# D1H register map
Vendor: Allwinner; File version: 1.0
Registers are 32-bit, read-write, reset 0x0 unless marked. A register's access mark holds for its fields unless they carry their own. Offsets are from the block's base; [hi:lo] are bit positions; {n}, {i} and the like mark numbered series; 'fields as' and 'values as' point back to an identical list.

## GPIO — Gerneral Purpose Input/Output
Base 0x02000000
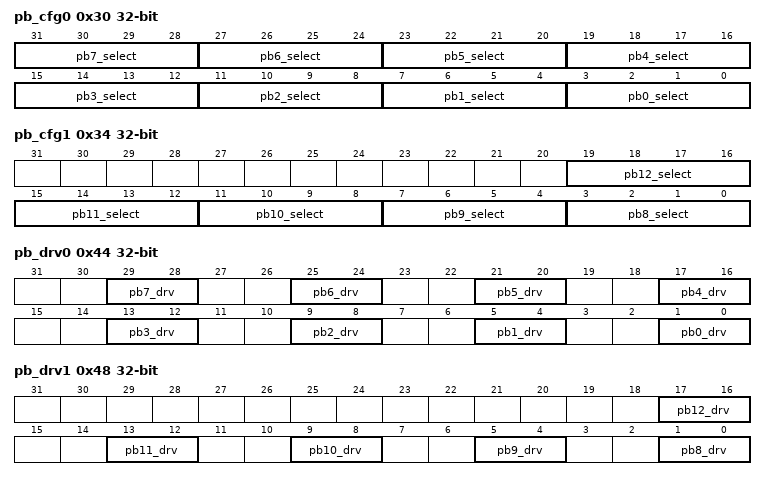
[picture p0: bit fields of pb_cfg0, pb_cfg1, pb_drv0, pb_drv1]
0x30 pb_cfg0 — PB Configure Register 0
  [31:28] pb7_select
    0=INPUT; 1=OUTPUT; 2=LCD0_D17; 3=I2_S2_MCLK; 4=TWI3_SDA; 5=IR_RX; 6=LCD0_D23; 7=UART3_RX; 8=CPUBIST1; 14=PB_EINT7; 15=IO_DISABLE
  [27:24] pb6_select
    0=INPUT; 1=OUTPUT; 2=LCD0_D16; 3=I2_S2_LRCK; 4=TWI3_SCK; 5=PWM1; 6=LCD0_D22; 7=UART3_TX; 8=CPUBIST0; 14=PB_EINT6; 15=IO_DISABLE
  [23:20] pb5_select
    0=INPUT; 1=OUTPUT; 2=LCD0_D9; 3=I2_S2_BCLK; 4=TWI1_SDA; 5=PWM0; 6=LCD0_D21; 7=UART5_RX; 14=PB_EINT5; 15=IO_DISABLE
  [19:16] pb4_select
    0=INPUT; 1=OUTPUT; 2=LCD0_D8; 3=I2_S2_DOUT0; 4=TWI1_SCK; 5=I2_S2_DIN1; 6=LCD0_D20; 7=UART5_TX; 14=PB_EINT4; 15=IO_DISABLE
  [15:12] pb3_select
    0=INPUT; 1=OUTPUT; 2=LCD0_D1; 3=I2_S2_DOUT1; 4=TWI0_SCK; 5=I2_S2_DIN0; 6=LCD0_D19; 7=UART4_RX; 14=PB_EINT3; 15=IO_DISABLE
  [11:8] pb2_select
    0=INPUT; 1=OUTPUT; 2=LCD0_D0; 3=I2_S2_DOUT2; 4=TWI0_SDA; 5=I2_S2_DIN2; 6=LCD0_D18; 7=UART4_TX; 14=PB_EINT2; 15=IO_DISABLE
  [7:4] pb1_select
    0=INPUT; 1=OUTPUT; 2=PWM4; 3=I2_S2_DOUT3; 4=TWI2_SDA; 5=I2_S2_DIN3; 6=UART0_RX; 7=UART2_RX; 8=IR_RX; 14=PB_EINT1; 15=IO_DISABLE
  [3:0] pb0_select
    0=INPUT; 1=OUTPUT; 2=PWM3; 3=IR_TX; 4=TWI2_SCK; 5=SPI1_WP_DBI_TE; 6=UART0_TX; 7=UART2_TX; 8=OWA_OUT; 14=PB_EINT0; 15=IO_DISABLE
0x34 pb_cfg1 — PB Configure Register 1
  [19:16] pb12_select
    0=INPUT; 1=OUTPUT; 2=DMIC_CLK; 3=PWM0; 4=OWA_IN; 5=SPI1_CS_DBI_CSX; 6=CLK_FANOUT2; 7=IR_RX; 14=PB_EINT12; 15=IO_DISABLE
  [15:12] pb11_select
    0=INPUT; 1=OUTPUT; 2=DMIC_DATA0; 3=PWM2; 4=TWI0_SDA; 5=SPI1_CLK_DBI_SCLK; 6=CLK_FANOUT1; 7=UART1_CTS; 14=PB_EINT11; 15=IO_DISABLE
  [11:8] pb10_select
    0=INPUT; 1=OUTPUT; 2=DMIC_DATA1; 3=PWM7; 4=TWI0_SCK; 5=SPI1_MOSI_DBI_SDO; 6=CLK_FANOUT0; 7=UART1_RTS; 14=PB_EINT10; 15=IO_DISABLE
  [7:4] pb9_select
    0=INPUT; 1=OUTPUT; 2=DMIC_DATA2; 3=PWM6; 4=TWI2_SDA; 5=SPI1_MISO_DBI_SDI_DBI_TE_DBI_DCX; 6=UART0_RX; 7=UART1_RX; 14=PB_EINT9; 15=IO_DISABLE
  [3:0] pb8_select
    0=INPUT; 1=OUTPUT; 2=DMIC_DATA3; 3=PWM5; 4=TWI2_SCK; 5=SPI1_HOLD_DBI_DCX_DBI_WRX; 6=UART0_TX; 7=UART1_TX; 14=PB_EINT8; 15=IO_DISABLE
0x40 pb_dat — PB Data Register
  [12:0] pb_dat
0x44 pb_drv0 — PB Multi_Driving Register 0
  [4n+1:4n] pb{n}_drv (n=0..7) — PB Multi_Driving Select
    {v}=L{v} (v=0..3)
0x48 pb_drv1 — PB Multi_Driving Register 1
  [4n-31:4n-32] pb{n}_drv (n=8..12) — PB Multi_Driving Select
    {v}=L{v} (v=0..3)
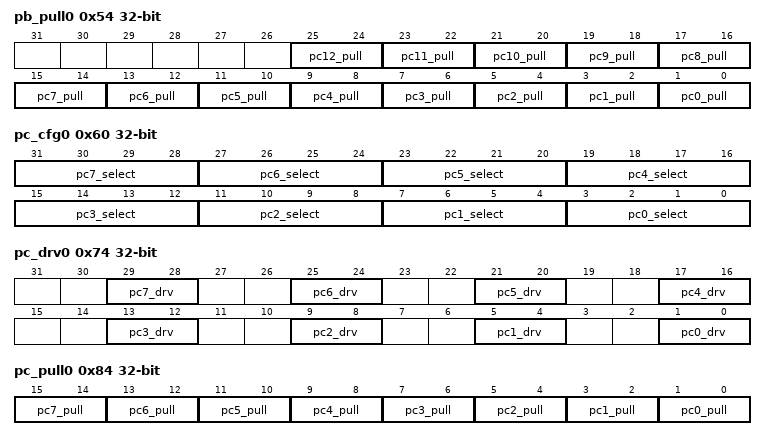
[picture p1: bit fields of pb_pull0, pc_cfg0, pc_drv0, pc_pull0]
0x54 pb_pull0 — PB Pull Register 0
  [2n+1:2n] pc{n}_pull (n=0..12) — PC Pull_up/down Select
    0=PULL_DISABLE; 1=PULL_UP; 2=PULL_DOWN
0x60 pc_cfg0 — PC Configure Register 0
  [31:28] pc7_select
    0=INPUT; 2=SPI0_HOLD; 4=UART3_RX; 6=TCON_TRIG; 14=PC_EINT7; 1=OUTPUT; 3=SDC2_D3; 5=TWI3_SDA; 15=IO_DISABLE
  [27:24] pc6_select
    0=INPUT; 2=SPI0_WP; 4=UART3_TX; 6=DBG_CLK; 14=PC_EINT6; 1=OUTPUT; 3=SDC2_D0; 5=TWI3_SCK; 15=IO_DISABLE
  [23:20] pc5_select
    0=INPUT; 2=SPI0_MISO; 4=BOOT_SEL1; 14=PC_EINT5; 1=OUTPUT; 3=SDC2_D1; 15=IO_DISABLE
  [19:16] pc4_select
    0=INPUT; 2=SPI0_MOSI; 4=BOOT_SEL0; 14=PC_EINT4; 1=OUTPUT; 3=SDC2_D2; 15=IO_DISABLE
  [15:12] pc3_select
    0=INPUT; 2=SPI0_CS0; 14=PC_EINT3; 1=OUTPUT; 3=SDC2_CMD; 15=IO_DISABLE
  [11:8] pc2_select
    0=INPUT; 2=SPI0_CLK; 14=PC_EINT2; 1=OUTPUT; 3=SDC2_CLK; 15=IO_DISABLE
  [7:4] pc1_select
    0=INPUT; 2=UART2_RX; 14=PC_EINT1; 1=OUTPUT; 3=TWI2_SDA; 15=IO_DISABLE
  [3:0] pc0_select
    0=INPUT; 2=UART2_TX; 4=LEDC_DO; 14=PC_EINT0; 1=OUTPUT; 3=TWI2_SCK; 15=IO_DISABLE
0x70 pc_dat — PC Data Register
  [7:0] pc_dat
0x74 pc_drv0 — PC Multi_Driving Register 0
  [4n+1:4n] pc{n}_drv (n=0..7) — PC Multi_Driving Select
    {v}=L{v} (v=0..3)
0x84 pc_pull0 — PC Pull Register 0
  [2n+1:2n] pc{n}_pull (n=0..7) — PC Pull_up/down Select
    0=PULL_DISABLE; 1=PULL_UP; 2=PULL_DOWN
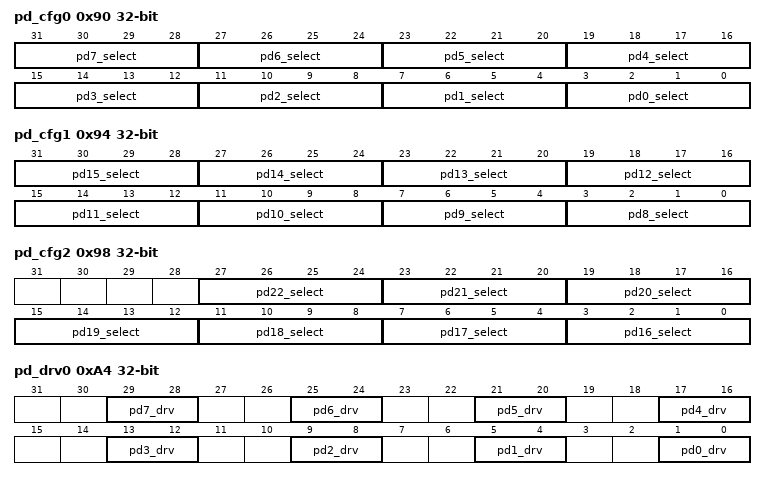
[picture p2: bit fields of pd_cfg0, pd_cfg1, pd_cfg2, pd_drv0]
0x90 pd_cfg0 — PD Configure Register 0
  [31:28] pd7_select
    0=INPUT; 2=LCD0_D11; 4=DSI_D2N; 14=PD_EINT7; 1=OUTPUT; 3=LVDS0_CKN; 5=UART4_TX; 15=IO_DISABLE
  [27:24] pd6_select
    0=INPUT; 2=LCD0_D10; 4=DSI_D2P; 14=PD_EINT6; 1=OUTPUT; 3=LVDS0_CKP; 5=UART5_RX; 15=IO_DISABLE
  [23:20] pd5_select
    0=INPUT; 2=LCD0_D7; 4=DSI_CKN; 14=PD_EINT5; 1=OUTPUT; 3=LVDS0_V2N; 5=UART5_TX; 15=IO_DISABLE
  [19:16] pd4_select
    0=INPUT; 2=LCD0_D6; 4=DSI_CKP; 14=PD_EINT4; 1=OUTPUT; 3=LVDS0_V2P; 5=UART2_CTS; 15=IO_DISABLE
  [15:12] pd3_select
    0=INPUT; 2=LCD0_D5; 4=DSI_D1N; 14=PD_EINT3; 1=OUTPUT; 3=LVDS0_V1N; 5=UART2_RTS; 15=IO_DISABLE
  [11:8] pd2_select
    0=INPUT; 2=LCD0_D4; 4=DSI_D1P; 14=PD_EINT2; 1=OUTPUT; 3=LVDS0_V1P; 5=UART2_RX; 15=IO_DISABLE
  [7:4] pd1_select
    0=INPUT; 2=LCD0_D3; 4=DSI_D0N; 14=PD_EINT1; 1=OUTPUT; 3=LVDS0_V0N; 5=UART2_TX; 15=IO_DISABLE
  [3:0] pd0_select
    0=INPUT; 2=LCD0_D2; 4=DSI_D0P; 14=PD_EINT0; 1=OUTPUT; 3=LVDS0_V0P; 5=TWI0_SCK; 15=IO_DISABLE
0x94 pd_cfg1 — PD Configure Register 1
  [31:28] pd15_select
    0=INPUT; 2=LCD0_D21; 4=SPI1_WP_DBI_TE; 14=PD_EINT15; 1=OUTPUT; 3=LVDS1_V2N; 5=IR_RX; 15=IO_DISABLE
  [27:24] pd14_select
    0=INPUT; 2=LCD0_D20; 4=SPI1_HOLD_DBI_DCX_DBI_WRX; 14=PD_EINT14; 1=OUTPUT; 3=LVDS1_V2P; 5=UART3_CTS; 15=IO_DISABLE
  [23:20] pd13_select
    0=INPUT; 1=OUTPUT; 2=LCD0_D19; 3=LVDS1_V1N; 4=SPI1_MISO_DBI_SDI_DBI_TE_DBI_DCX; 5=UART3_RTS; 14=PD_EINT13; 15=IO_DISABLE
  [19:16] pd12_select
    0=INPUT; 2=LCD0_D18; 4=SPI1_MOSI_DBI_SDO; 14=PD_EINT12; 1=OUTPUT; 3=LVDS1_V1P; 5=TWI0_SDA; 15=IO_DISABLE
  [15:12] pd11_select
    0=INPUT; 2=LCD0_D15; 4=SPI1_CLK_DBI_SCLK; 14=PD_EINT11; 1=OUTPUT; 3=LVDS1_V0N; 5=UART3_RX; 15=IO_DISABLE
  [11:8] pd10_select
    0=INPUT; 2=LCD0_D14; 4=SPI1_CS_DBI_CSX; 14=PD_EINT10; 1=OUTPUT; 3=LVDS1_V0P; 5=UART3_TX; 15=IO_DISABLE
  [7:4] pd9_select
    0=INPUT; 2=LCD0_D13; 4=DSI_D3N; 14=PD_EINT9; 1=OUTPUT; 3=LVDS0_V3N; 5=PWM6; 15=IO_DISABLE
  [3:0] pd8_select
    0=INPUT; 2=LCD0_D12; 4=DSI_D3P; 14=PD_EINT8; 1=OUTPUT; 3=LVDS0_V3P; 5=UART4_RX; 15=IO_DISABLE
0x98 pd_cfg2 — PD Configure Register 2
  [27:24] pd22_select
    0=INPUT; 2=OWA_OUT; 4=UART1_RX; 14=PD_EINT22; 1=OUTPUT; 3=IR_RX; 5=PWM7; 15=IO_DISABLE
  [23:20] pd21_select
    0=INPUT; 2=LCD0_VSYNC; 4=UART1_TX; 14=PD_EINT21; 1=OUTPUT; 3=TWI2_SDA; 5=PWM5; 15=IO_DISABLE
  [19:16] pd20_select
    0=INPUT; 2=LCD0_HSYNC; 4=DMIC_CLK; 14=PD_EINT20; 1=OUTPUT; 3=TWI2_SCK; 5=PWM4; 15=IO_DISABLE
  [15:12] pd19_select
    0=INPUT; 2=LCD0_DE; 4=DMIC_DATA0; 14=PD_EINT19; 1=OUTPUT; 3=LVDS1_V3N; 5=PWM3; 15=IO_DISABLE
  [11:8] pd18_select
    0=INPUT; 2=LCD0_CLK; 4=DMIC_DATA1; 14=PD_EINT18; 1=OUTPUT; 3=LVDS1_V3P; 5=PWM2; 15=IO_DISABLE
  [7:4] pd17_select
    0=INPUT; 2=LCD0_D23; 4=DMIC_DATA2; 14=PD_EINT17; 1=OUTPUT; 3=LVDS1_CKN; 5=PWM1; 15=IO_DISABLE
  [3:0] pd16_select
    0=INPUT; 2=LCD0_D22; 4=DMIC_DATA3; 14=PD_EINT16; 1=OUTPUT; 3=LVDS1_CKP; 5=PWM0; 15=IO_DISABLE
0xA0 pd_dat — PD Data Register
  [22:0] pd_dat
0xA4 pd_drv0 — PD Multi_Driving Register 0
  [4n+1:4n] pd{n}_drv (n=0..7) — PD Multi_Driving Select
    {v}=L{v} (v=0..3)
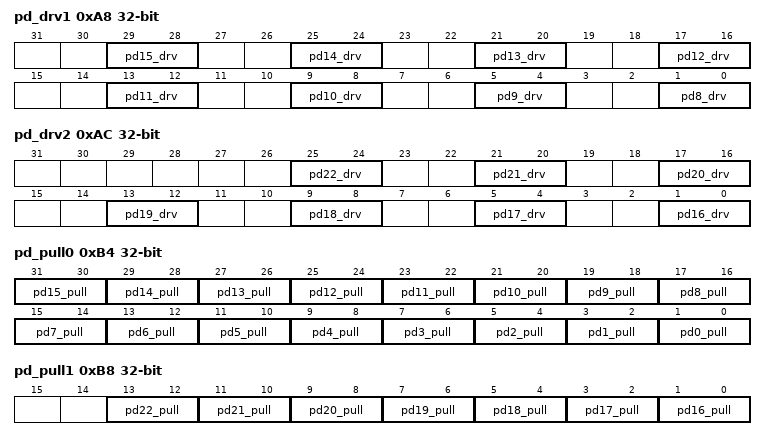
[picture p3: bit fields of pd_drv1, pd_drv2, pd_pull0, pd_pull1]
0xA8 pd_drv1 — PD Multi_Driving Register 1
  [4n-31:4n-32] pd{n}_drv (n=8..15) — PD Multi_Driving Select
    {v}=L{v} (v=0..3)
0xAC pd_drv2 — PD Multi_Driving Register 2
  [4n-63:4n-64] pd{n}_drv (n=16..22) — PD Multi_Driving Select
    {v}=L{v} (v=0..3)
0xB4 pd_pull0 — PD Pull Register 0
  [2n+1:2n] pd{n}_pull (n=0..15) — PD Pull_up/down Select
    0=PULL_DISABLE; 1=PULL_UP; 2=PULL_DOWN
0xB8 pd_pull1 — PD Pull Register 1
  [2n-31:2n-32] pd{n}_pull (n=16..22) — PD Pull_up/down Select
    0=PULL_DISABLE; 1=PULL_UP; 2=PULL_DOWN
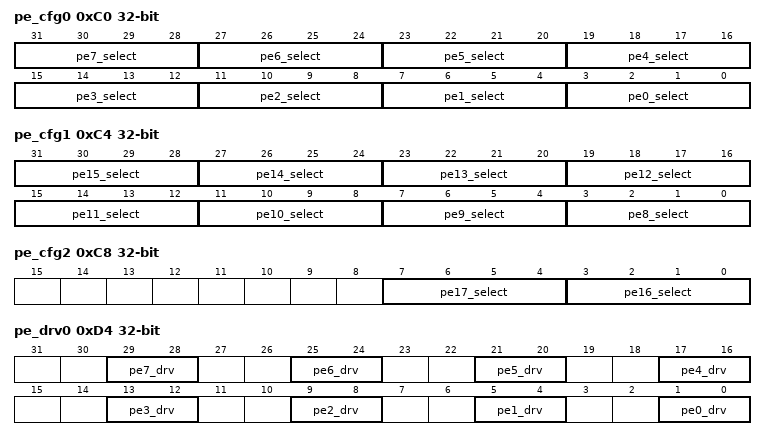
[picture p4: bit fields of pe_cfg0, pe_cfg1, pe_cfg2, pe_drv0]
0xC0 pe_cfg0 — PE Configure Register 0
  [31:28] pe7_select
    0=INPUT; 2=NCSI0_D3; 4=TWI3_SDA; 6=D_JTAG_CK; 8=RGMII_CLKIN_RMII_RXER; 14=PE_EINT7; 15=IO_DISABLE; 1=OUTPUT; 3=UART5_RX; 5=OWA_OUT; 7=R_JTAG_CK
  [27:24] pe6_select
    0=INPUT; 2=NCSI0_D2; 4=TWI3_SCK; 6=D_JTAG_DO; 8=RMII_TXCTRL_RMII_TXEN; 14=PE_EINT6; 15=IO_DISABLE; 1=OUTPUT; 3=UART5_TX; 5=OWA_IN; 7=R_JTAG_DO
  [23:20] pe5_select
    0=INPUT; 2=NCSI0_D1; 4=TWI2_SDA; 6=D_JTAG_DI; 8=RGMII_TXD1_RMII_TXD1; 14=PE_EINT5; 15=IO_DISABLE; 1=OUTPUT; 3=UART4_RX; 5=LEDC_DO; 7=R_JTAG_DI
  [19:16] pe4_select
    0=INPUT; 2=NCSI0_D0; 4=TWI2_SCK; 6=D_JTAG_MS; 8=RGMII_TXD0_RMII_TXD0; 14=PE_EINT4; 15=IO_DISABLE; 1=OUTPUT; 3=UART4_TX; 5=CLK_FANOUT2; 7=R_JTAG_MS
  [15:12] pe3_select
    0=INPUT; 2=NCSI0_MCLK; 4=TWI0_SDA; 6=UART0_RX; 8=RGMII_TXCK_RMII_TXCK; 14=PE_EINT3; 15=IO_DISABLE; 1=OUTPUT; 3=UART2_RX; 5=CLK_FANOUT1
  [11:8] pe2_select
    0=INPUT; 2=NCSI0_PCLK; 4=TWI0_SCK; 6=UART0_TX; 8=RGMII_RXD1_RMII_RXD1; 14=PE_EINT2; 15=IO_DISABLE; 1=OUTPUT; 3=UART2_TX; 5=CLK_FANOUT0
  [7:4] pe1_select
    0=INPUT; 2=NCSI0_VSYNC; 4=TWI1_SDA; 8=RGMII_RXD0_RMII_RXD0; 14=PE_EINT1; 1=OUTPUT; 3=UART2_CTS; 5=LCD0_VSYNC; 15=IO_DISABLE
  [3:0] pe0_select
    0=INPUT; 2=NCSI0_HSYNC; 4=TWI1_SCK; 8=RGMII_RXCTRL_RMII_CRS_DV; 14=PE_EINT0; 1=OUTPUT; 3=UART2_RTS; 5=LCD0_HSYNC; 15=IO_DISABLE
0xC4 pe_cfg1 — PE Configure Register 1
  [31:28] pe15_select
    0=INPUT; 2=TWI1_SDA; 4=PWM6; 6=DMIC_DATA1; 8=RGMII_RXCK; 14=PE_EINT15; 1=OUTPUT; 3=D_JTAG_DI; 5=I2S0_LRCK; 15=IO_DISABLE
  [27:24] pe14_select
    0=INPUT; 2=TWI1_SCK; 4=I2S0_DOUT1; 6=DMIC_DATA2; 8=RGMII_RXD3; 14=PE_EINT14; 1=OUTPUT; 3=D_JTAG_MS; 5=I2S0_DIN0; 15=IO_DISABLE
  [23:20] pe13_select
    0=INPUT; 2=TWI2_SDA; 4=I2S0_DOUT0; 6=DMIC_DATA3; 8=RGMII_RXD2; 14=PE_EINT13; 1=OUTPUT; 3=PWM5; 5=I2S0_DIN1; 15=IO_DISABLE
  [19:16] pe12_select
    0=INPUT; 2=TWI2_SCK; 4=I2S0_DOUT2; 8=RGMII_TXD3; 14=PE_EINT12; 1=OUTPUT; 3=NCSI0_FIELD; 5=I2S0_DIN2; 15=IO_DISABLE
  [15:12] pe11_select
    0=INPUT; 2=NCSI0_D7; 4=I2S0_DOUT3; 6=JTAG_CK; 8=RGMII_TXD2; 14=PE_EINT11; 1=OUTPUT; 3=UART1_RX; 5=I2S0_DIN3; 15=IO_DISABLE
  [11:8] pe10_select
    0=INPUT; 2=NCSI0_D6; 4=PWM4; 6=JTAG_DO; 8=EPHY_25M; 14=PE_EINT10; 1=OUTPUT; 3=UART1_TX; 5=IR_RX; 15=IO_DISABLE
  [7:4] pe9_select
    0=INPUT; 2=NCSI0_D5; 4=PWM3; 6=JTAG_DI; 8=MDIO; 14=PE_EINT9; 1=OUTPUT; 3=UART1_CTS; 5=UART3_RX; 15=IO_DISABLE
  [3:0] pe8_select
    0=INPUT; 2=NCSI0_D4; 4=PWM2; 6=JTAG_MS; 8=MDC; 14=PE_EINT8; 1=OUTPUT; 3=UART1_RTS; 5=UART3_TX; 15=IO_DISABLE
0xC8 pe_cfg2 — PE Configure Register 2
  [7:4] pe17_select
    0=INPUT; 2=TWI3_SDA; 4=IR_TX; 6=DMIC_CLK; 14=PE_EINT17; 1=OUTPUT; 3=D_JTAG_CK; 5=I2S0_MCLK; 15=IO_DISABLE
  [3:0] pe16_select
    0=INPUT; 2=TWI3_SCK; 4=PWM7; 6=DMIC_DATA0; 14=PE_EINT16; 1=OUTPUT; 3=D_JTAG_DO; 5=I2S0_BCLK; 15=IO_DISABLE
0xD0 pe_dat — PE Data Register
  [17:0] pe_dat — PE Data
0xD4 pe_drv0 — PE Multi_Driving Register 0
  [4n+1:4n] pe{n}_drv (n=0..7) — PE Multi_Driving Select
    {v}=L{v} (v=0..3)
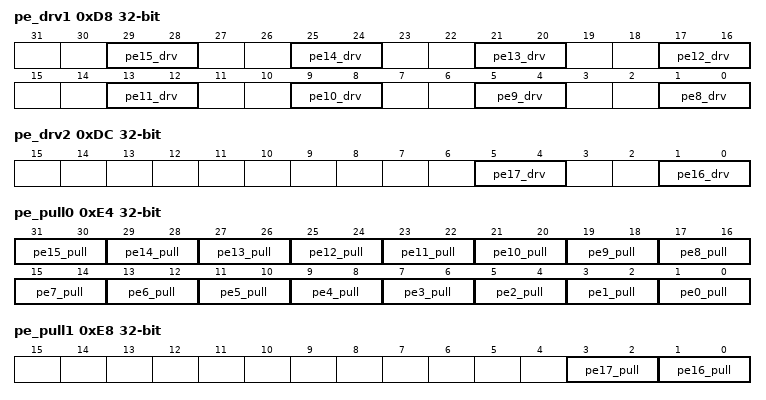
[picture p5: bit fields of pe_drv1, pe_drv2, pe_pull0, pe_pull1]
0xD8 pe_drv1 — PE Multi_Driving Register 1
  [4n-31:4n-32] pe{n}_drv (n=8..15) — PE Multi_Driving Select
    {v}=L{v} (v=0..3)
0xDC pe_drv2 — PE Multi_Driving Register 2
  [4n-63:4n-64] pe{n}_drv (n=16..17) — PE Multi_Driving Select
    {v}=L{v} (v=0..3)
0xE4 pe_pull0 — PE Pull Register 0
  [2n+1:2n] pe{n}_pull (n=0..15) — PE Pull_up/down Select
    0=PULL_DISABLE; 1=PULL_UP; 2=PULL_DOWN
0xE8 pe_pull1 — PE Pull Register 1
  [2n-31:2n-32] pe{n}_pull (n=16..17) — PE Pull_up/down Select
    0=PULL_DISABLE; 1=PULL_UP; 2=PULL_DOWN
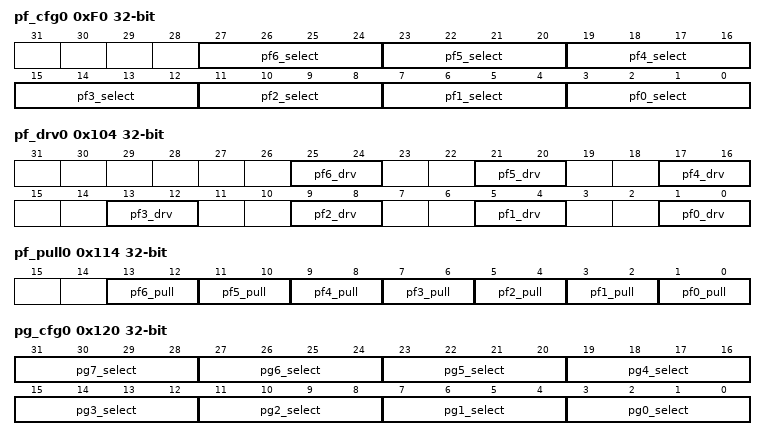
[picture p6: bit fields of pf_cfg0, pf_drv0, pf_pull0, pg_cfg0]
0xF0 pf_cfg0 — PF Configure Register 0
  [27:24] pf6_select
    0=INPUT; 4=IR_RX; 6=PWM5; 14=PF_EINT6; 1=OUTPUT; 3=OWA_OUT; 5=I2S2_MCLK; 15=IO_DISABLE
  [23:20] pf5_select
    0=INPUT; 2=SDC0_D2; 4=R_JTAG_CK; 14=PF_EINT5; 1=OUTPUT; 3=JTAG_CK; 5=I2S2_LRCK; 15=IO_DISABLE
  [19:16] pf4_select
    0=INPUT; 2=SDC0_D3; 4=TWI0_SDA; 6=IR_TX; 14=PF_EINT4; 1=OUTPUT; 3=UART0_RX; 5=PWM6; 15=IO_DISABLE
  [15:12] pf3_select
    0=INPUT; 2=SDC0_CMD; 4=R_JTAG_DO; 14=PF_EINT3; 1=OUTPUT; 3=JTAG_DO; 5=I2S2_BCLK; 15=IO_DISABLE
  [11:8] pf2_select
    0=INPUT; 2=SDC0_CLK; 4=TWI0_SCK; 6=OWA_IN; 14=PF_EINT2; 1=OUTPUT; 3=UART0_TX; 5=LEDC_DO; 15=IO_DISABLE
  [7:4] pf1_select
    0=INPUT; 2=SDC0_D0; 4=R_JTAG_DI; 6=I2S2_DIN1; 14=PF_EINT1; 1=OUTPUT; 3=JTAG_DI; 5=I2S2_DOUT0; 15=IO_DISABLE
  [3:0] pf0_select
    0=INPUT; 2=SDC0_D1; 4=R_JTAG_MS; 6=I2S2_DIN0; 14=PF_EINT0; 1=OUTPUT; 3=JTAG_MS; 5=I2S2_DOUT1; 15=IO_DISABLE
0x100 pf_dat — PF Data Register
  [6:0] pf_dat — PF Data
0x104 pf_drv0 — PF Multi_Driving Register 0
  [4n+1:4n] pf{n}_drv (n=0..6) — PF Multi_Driving Select
    {v}=L{v} (v=0..3)
0x114 pf_pull0 — PF Pull Register 0
  [2n+1:2n] pf{n}_pull (n=0..6) — PF Pull_up/down Select
    0=PULL_DISABLE; 1=PULL_UP; 2=PULL_DOWN
0x120 pg_cfg0 — PG Configure Register 0
  [31:28] pg7_select
    0=INPUT; 2=UART1_RX; 4=RGMII_TXD3; 14=PG_EINT7; 1=OUTPUT; 3=TWI2_SDA; 5=OWA_IN; 15=IO_DISABLE
  [27:24] pg6_select
    0=INPUT; 2=UART1_TX; 4=RGMII_TXD2; 14=PG_EINT6; 1=OUTPUT; 3=TWI2_SCK; 5=PWM1; 15=IO_DISABLE
  [23:20] pg5_select
    0=INPUT; 2=SDC1_D3; 4=RGMII_TXD1_RMII_TXD1; 14=PG_EINT5; 1=OUTPUT; 3=UART5_RX; 5=PWM4; 15=IO_DISABLE
  [19:16] pg4_select
    0=INPUT; 2=SDC1_D2; 4=RGMII_TXD0_RMII_TXD0; 14=PG_EINT4; 1=OUTPUT; 3=UART5_TX; 5=PWM5; 15=IO_DISABLE
  [15:12] pg3_select
    0=INPUT; 2=SDC1_D1; 4=RGMII_TXCK_RMII_TXCK; 14=PG_EINT3; 1=OUTPUT; 3=UART3_CTS; 5=UART4_RX; 15=IO_DISABLE
  [11:8] pg2_select
    0=INPUT; 2=SDC1_D0; 4=RGMII_RXD1_RMII_RXD1; 14=PG_EINT2; 1=OUTPUT; 3=UART3_RTS; 5=UART4_TX; 15=IO_DISABLE
  [7:4] pg1_select
    0=INPUT; 2=SDC1_CMD; 4=RGMII_RXD0_RMII_RXD0; 14=PG_EINT1; 1=OUTPUT; 3=UART3_RX; 5=PWM6; 15=IO_DISABLE
  [3:0] pg0_select
    0=INPUT; 2=SDC1_CLK; 4=RGMII_RXCTRL_RMII_CRS_DV; 14=PG_EINT0; 1=OUTPUT; 3=UART3_TX; 5=PWM7; 15=IO_DISABLE
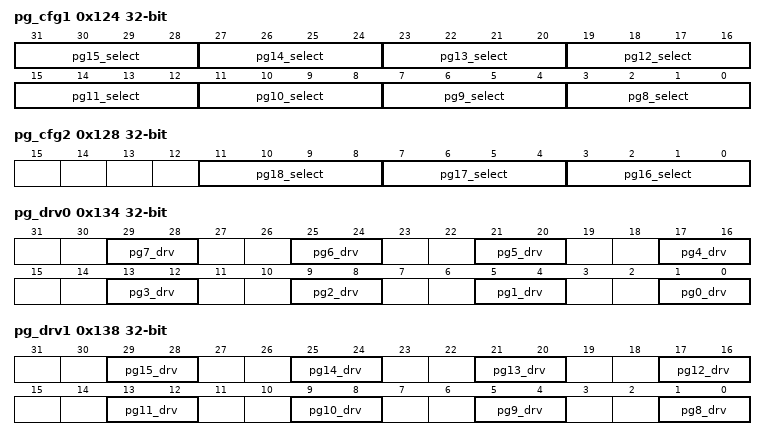
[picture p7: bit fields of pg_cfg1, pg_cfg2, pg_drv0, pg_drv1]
0x124 pg_cfg1 — PG Configure Register 1
  [31:28] pg15_select
    0=INPUT; 2=I2S1_DOUT0; 4=MDIO; 6=SPI0_HOLD; 14=PG_EINT15; 1=OUTPUT; 3=TWI2_SDA; 5=I2S1_DIN1; 7=UART1_CTS; 15=IO_DISABLE
  [27:24] pg14_select
    0=INPUT; 2=I2S1_DIN0; 4=MDC; 6=SPI0_WP; 14=PG_EINT14; 1=OUTPUT; 3=TWI2_SCK; 5=I2S1_DOUT1; 7=UART1_RTS; 15=IO_DISABLE
  [23:20] pg13_select
    0=INPUT; 2=I2S1_BCLK; 4=RGMII_CLKIN_RMII_RXER; 6=LEDC_DO; 14=PG_EINT13; 1=OUTPUT; 3=TWI0_SDA; 5=PWM2; 7=UART1_RX; 15=IO_DISABLE
  [19:16] pg12_select
    0=INPUT; 1=OUTPUT; 2=I2S1_LRCK; 3=TWI0_SCK; 4=RGMII_TXCTRL_RMII_TXEN; 5=CLK_FANOUT2; 6=PWM0; 14=PG_EINT12; 7=UART1_TX; 15=IO_DISABLE
  [15:12] pg11_select
    0=INPUT; 2=I2S1_MCLK; 4=EPHY_25M; 6=TCON_TRIG; 14=PG_EINT11; 1=OUTPUT; 3=TWI3_SDA; 5=CLK_FANOUT1; 15=IO_DISABLE
  [11:8] pg10_select
    0=INPUT; 2=PWM3; 4=RGMII_RXCK; 6=IR_RX; 14=PG_EINT10; 1=OUTPUT; 3=TWI3_SCK; 5=CLK_FANOUT0; 15=IO_DISABLE
  [7:4] pg9_select
    0=INPUT; 2=UART1_CTS; 4=RGMII_RXD3; 14=PG_EINT9; 1=OUTPUT; 3=TWI1_SDA; 5=UART3_RX; 15=IO_DISABLE
  [3:0] pg8_select
    0=INPUT; 2=UART1_RTS; 4=RGMII_RXD2; 14=PG_EINT8; 1=OUTPUT; 3=TWI1_SCK; 5=UART3_TX; 15=IO_DISABLE
0x128 pg_cfg2 — PG Configure Register 2
  [11:8] pg18_select
    0=INPUT; 2=UART2_RX; 4=PWM6; 6=OWA_OUT; 14=PG_EINT18; 1=OUTPUT; 3=TWI3_SDA; 5=CLK_FANOUT1; 7=UART0_RX; 15=IO_DISABLE
  [7:4] pg17_select
    0=INPUT; 2=UART2_TX; 4=PWM7; 6=IR_TX; 14=PG_EINT17; 1=OUTPUT; 3=TWI3_SCK; 5=CLK_FANOUT0; 7=UART0_TX; 15=IO_DISABLE
  [3:0] pg16_select
    0=INPUT; 2=IR_RX; 4=PWM5; 6=OWA_IN; 14=PG_EINT16; 1=OUTPUT; 3=TCON_TRIG; 5=CLK_FANOUT2; 7=LEDC_DO; 15=IO_DISABLE
0x130 pg_dat — PG Data Register
  [18:0] pg_dat — PG Data
0x134 pg_drv0 — PG Multi_Driving Register 0
  [4n+1:4n] pg{n}_drv (n=0..7) — PG Multi_Driving Select
    {v}=L{v} (v=0..3)
0x138 pg_drv1 — PG Multi_Driving Register 1
  [4n-31:4n-32] pg{n}_drv (n=8..15) — PG Multi_Driving Select
    {v}=L{v} (v=0..3)
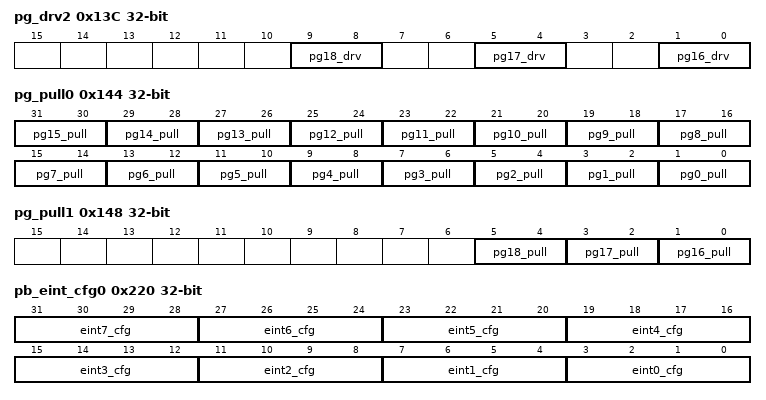
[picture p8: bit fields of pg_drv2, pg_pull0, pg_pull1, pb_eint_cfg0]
0x13C pg_drv2 — PG Multi_Driving Register 2
  [4n-63:4n-64] pg{n}_drv (n=16..18) — PG Multi_Driving Select
    {v}=L{v} (v=0..3)
0x144 pg_pull0 — PG Pull Register 0
  [2n+1:2n] pg{n}_pull (n=0..15) — PG Pull_up/down Select
    0=PULL_DISABLE; 1=PULL_UP; 2=PULL_DOWN
0x148 pg_pull1 — PG Pull Register 1
  [2n-31:2n-32] pg{n}_pull (n=16..18) — PG Pull_up/down Select
    0=PULL_DISABLE; 1=PULL_UP; 2=PULL_DOWN
0x220 pb_eint_cfg0 — PB External Interrupt Configure Register 0
  [4n+3:4n] eint{n}_cfg (n=0..7) — External INT Mode
    0=POSITIVE_EDGE; 1=NEGATIVE_EDGE; 2=HIGH_LEVEL; 3=LOW_LEVEL; 4=DOUBLE_EDGE
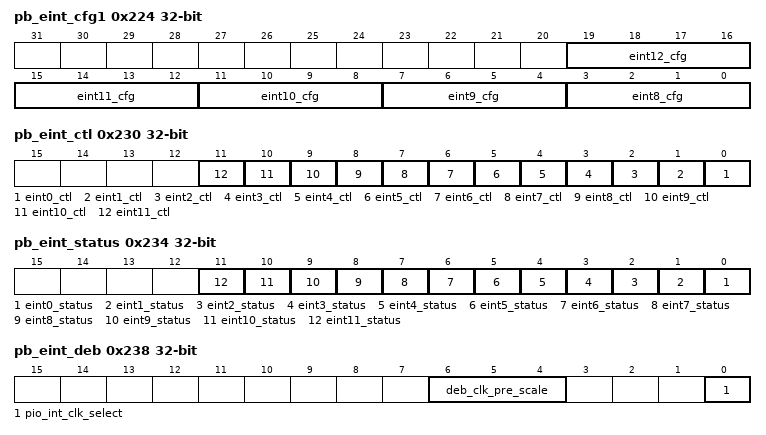
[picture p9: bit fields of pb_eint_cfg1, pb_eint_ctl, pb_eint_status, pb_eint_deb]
0x224 pb_eint_cfg1 — PB External Interrupt Configure Register 1
  [4n-29:4n-32] eint{n}_cfg (n=8..12) — External INT Mode
    values as pb_eint_cfg0.eint0_cfg
0x230 pb_eint_ctl — PB External Interrupt Control Register
  [n] eint{n}_ctl (n=0..11) — External INT Enable
    0=DISABLE; 1=ENABLE
0x234 pb_eint_status — PB External Interrupt Status Register
  [n] eint{n}_status (n=0..11) — External INT Pending Bit
    0=NO_PENDING; 1=PENDING
0x238 pb_eint_deb — PB External Interrupt Debounce Register
  [6:4] deb_clk_pre_scale — Debounce Clock Pre_scale n
  [0] pio_int_clk_select — PIO Interrupt Clock Select
    0=LOSC_32K_HZ; 1=HOSC_24M_HZ
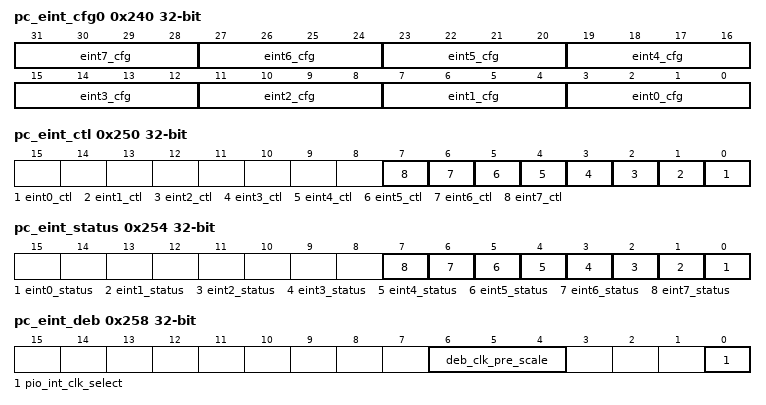
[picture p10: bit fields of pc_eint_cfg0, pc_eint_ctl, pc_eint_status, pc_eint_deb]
0x240 pc_eint_cfg0 — PC External Interrupt Configure Register 0
  fields as pb_eint_cfg0
0x250 pc_eint_ctl — PC External Interrupt Control Register
  [n] eint{n}_ctl (n=0..7) — External INT Enable
    0=DISABLE; 1=ENABLE
0x254 pc_eint_status — PC External Interrupt Status Register
  [n] eint{n}_status (n=0..7) — External INT Pending Bit
    0=NO_PENDING; 1=PENDING
0x258 pc_eint_deb — PC External Interrupt Debounce Register
  fields as pb_eint_deb
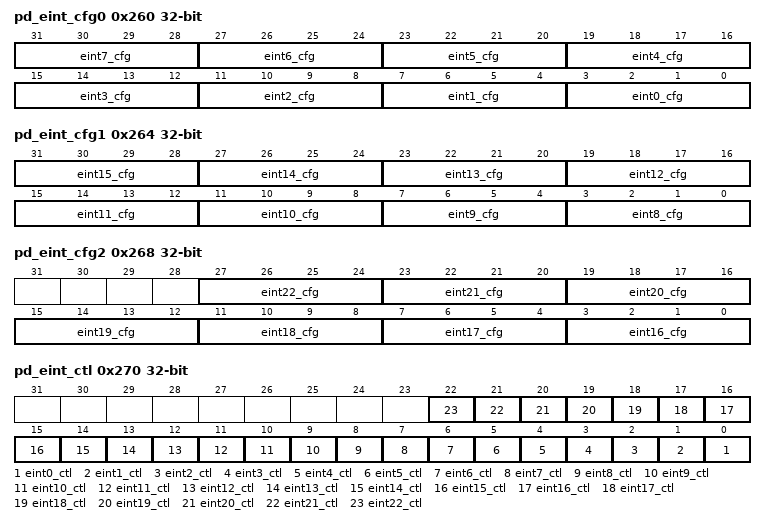
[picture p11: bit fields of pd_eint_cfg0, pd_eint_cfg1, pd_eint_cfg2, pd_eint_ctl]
0x260 pd_eint_cfg0 — PD External Interrupt Configure Register 0
  fields as pb_eint_cfg0
0x264 pd_eint_cfg1 — PD External Interrupt Configure Register 1
  [4n-29:4n-32] eint{n}_cfg (n=8..15) — External INT Mode
    values as pb_eint_cfg0.eint0_cfg
0x268 pd_eint_cfg2 — PD External Interrupt Configure Register 2
  [4n-61:4n-64] eint{n}_cfg (n=16..22) — External INT Mode
    values as pb_eint_cfg0.eint0_cfg
0x270 pd_eint_ctl — PD External Interrupt Control Register
  [n] eint{n}_ctl (n=0..22) — External INT Enable
    0=DISABLE; 1=ENABLE
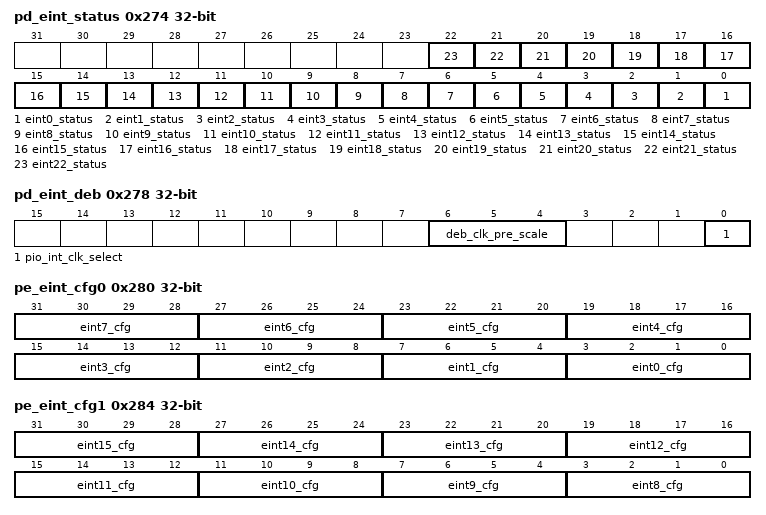
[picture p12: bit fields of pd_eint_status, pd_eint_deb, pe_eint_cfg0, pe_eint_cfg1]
0x274 pd_eint_status — PD External Interrupt Status Register
  [n] eint{n}_status (n=0..22) — External INT Pending Bit
    0=NO_PENDING; 1=PENDING
0x278 pd_eint_deb — PD External Interrupt Debounce Register
  fields as pb_eint_deb
0x280 pe_eint_cfg0 — PE External Interrupt Configure Register 0
  fields as pb_eint_cfg0
0x284 pe_eint_cfg1 — PE External Interrupt Configure Register 1
  fields as pd_eint_cfg1
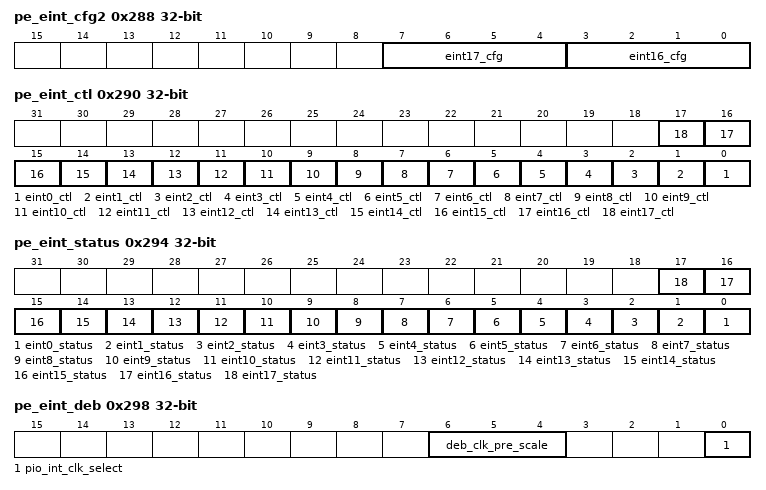
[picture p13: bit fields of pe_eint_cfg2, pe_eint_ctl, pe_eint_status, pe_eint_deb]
0x288 pe_eint_cfg2 — PE External Interrupt Configure Register 2
  [4n-61:4n-64] eint{n}_cfg (n=16..17) — External INT Mode
    values as pb_eint_cfg0.eint0_cfg
0x290 pe_eint_ctl — PE External Interrupt Control Register
  [n] eint{n}_ctl (n=0..17) — External INT Enable
    0=DISABLE; 1=ENABLE
0x294 pe_eint_status — PE External Interrupt Status Register
  [n] eint{n}_status (n=0..17) — External INT Pending Bit
    0=NO_PENDING; 1=PENDING
0x298 pe_eint_deb — PE External Interrupt Debounce Register
  fields as pb_eint_deb
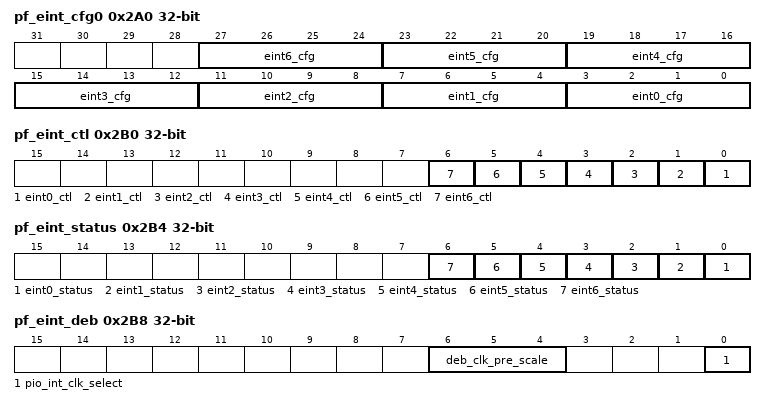
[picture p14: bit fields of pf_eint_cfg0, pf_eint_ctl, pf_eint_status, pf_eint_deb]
0x2A0 pf_eint_cfg0 — PF External Interrupt Configure Register 0
  [4n+3:4n] eint{n}_cfg (n=0..6) — External INT Mode
    values as pb_eint_cfg0.eint0_cfg
0x2B0 pf_eint_ctl — PF External Interrupt Control Register
  [n] eint{n}_ctl (n=0..6) — External INT Enable
    0=DISABLE; 1=ENABLE
0x2B4 pf_eint_status — PF External Interrupt Status Register
  [n] eint{n}_status (n=0..6) — External INT Pending Bit
    0=NO_PENDING; 1=PENDING
0x2B8 pf_eint_deb — PF External Interrupt Debounce Register
  fields as pb_eint_deb
0x2C0 pg_eint_cfg0 — PG External Interrupt Configure Register 0
  fields as pb_eint_cfg0
0x2C4 pg_eint_cfg1 — PG External Interrupt Configure Register 1
  fields as pd_eint_cfg1
0x2C8 pg_eint_cfg2 — PG External Interrupt Configure Register 2
  [4n-61:4n-64] eint{n}_cfg (n=16..18) — External INT Mode
    values as pb_eint_cfg0.eint0_cfg
0x2D0 pg_eint_ctl — PG External Interrupt Control Register
  [n] eint{n}_ctl (n=0..18) — External INT Enable
    0=DISABLE; 1=ENABLE
0x2D4 pg_eint_status — PG External Interrupt Status Register
  fields as pe_eint_status
0x2D8 pg_eint_deb — PG External Interrupt Debounce Register
  fields as pb_eint_deb
0x340 pio_pow_mod_sel — PIO Group Withstand Voltage Mode Select Register
  [12] vcc_io_pwr_mod_sel — VCC_IO POWER MODE Select
    0=V33 (3.3 V); 1=V18 (1.8 V)
  [2] p{x}_pwr_mod_sel (x=C,D,E,F,G; step 1) — PX_POWER POWER MODE Select
    0=V33 (3.3 V); 1=V18 (1.8 V)
0x344 pio_pow_ms_ctl — PIO Group Withstand Voltage Mode Select Control Register
  [12] vccio_ws_vol_mod_sel — VCC_IO Withstand Voltage Mode Select Control
    0=ENABLE; 1=DISABLE
  [2] vcc_p{x}_ws_vol_mod_sel (x=C,D,E,F,G; step 1) — VCC_PX Withstand Voltage Mode Select Control
    0=ENABLE; 1=DISABLE
0x348 pio_pow_val ro — PIO Group Power Value Register
  [12] vccio_pws_val — VCC_IO Power Value
  [2] p{x}_pwr_val (x=C,D,E,F,G; step 1) — PX_Port Power Value
0x350 pio_pow_vol_sel_ctl — PIO Group Power Voltage Select Control Register
  [0] vcc_pf_pwr_vol_sel — VCC_PF Power Voltage Select Control
    0=V18 (1.8V); 1=V33 (3.3V)
